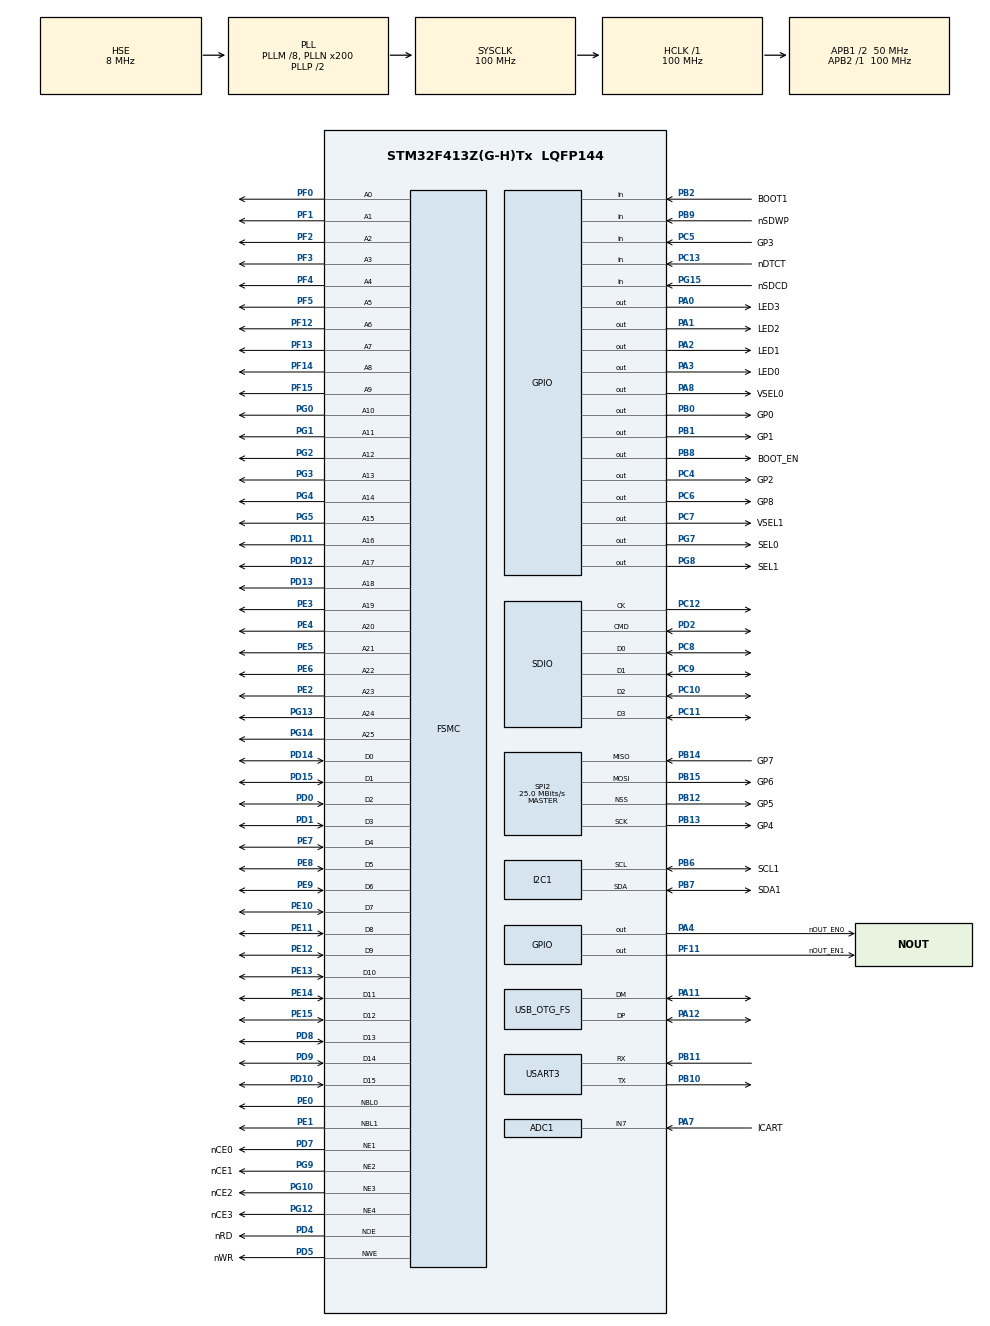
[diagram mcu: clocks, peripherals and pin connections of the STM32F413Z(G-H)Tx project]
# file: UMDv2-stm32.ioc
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SH.FSMC_D1_DA1.2=FSMC_D1,16b-d4
SH.FSMC_D1_DA1.1=FSMC_D1,8b-d2
SH.FSMC_D1_DA1.3=FSMC_D1,8b-d3
PD7.Mode=NorPsramChipSelect1_1
SH.FSMC_D1_DA1.0=FSMC_D1,8b-d1
FATFS0.BSP.api=Unknown
PG8.Signal=GPIO_Output
SH.FSMC_NWE.0=FSMC_NWE,Sram2
PG0.Signal=FSMC_A10
SH.FSMC_NWE.3=FSMC_NWE,Sram3
SH.FSMC_NWE.1=FSMC_NWE,Sram4
SH.FSMC_NWE.2=FSMC_NWE,Sram1
Dma.MEMTOMEM.1.FIFOMode=DMA_FIFOMODE_ENABLE
PG15.GPIO_Label=nSDCD
PB0.Stacked=true
RCC.APB2TimFreq_Value=100000000
PB6.Signal=I2C1_SCL
PC7.Signal=GPIO_Output
PD0.Signal=FSMC_D2_DA2
PD8.Signal=FSMC_D13_DA13
PE1.Signal=FSMC_NBL1
FATFS0.BSP.ip=GPIO
PB3.Mode=JTAG_5_pins
PB12.GPIO_Label=GP5
SH.FSMC_D10_DA10.0=FSMC_D10,16b-d4
PC4.GPIO_Label=GP2
PE9.Signal=FSMC_D6_DA6
PB1.GPIO_Label=GP1
PC9.Mode=SD_4_bits_Wide_bus
PA8.Signal=GPIO_Output
SH.FSMC_D5_DA5.0=FSMC_D5,8b-d1
SH.FSMC_D5_DA5.3=FSMC_D5,8b-d3
SH.FSMC_D5_DA5.1=FSMC_D5,8b-d2
PA0.Signal=GPIO_Output
SH.FSMC_D5_DA5.2=FSMC_D5,16b-d4
Mcu.Package=LQFP144
PB9.Signal=GPIO_Input
PB1.Signal=SharedStack_PB1
Dma.MEMTOMEM.1.Instance=DMA2_Stream1
SPI2.Mode=SPI_MODE_MASTER
PD12.Signal=FSMC_A17
PC11.Mode=SD_4_bits_Wide_bus
SH.FSMC_A1.1=FSMC_A1,26b-a3
SH.FSMC_A1.2=FSMC_A1,26b-a2
SH.FSMC_A1.0=FSMC_A1,26b-a1
SH.FSMC_A1.3=FSMC_A1,26b-a4
RCC.APB1TimFreq_Value=100000000
FSMC.WriteOperation3=FSMC_WRITE_OPERATION_ENABLE
FSMC.WriteOperation4=FSMC_WRITE_OPERATION_ENABLE
PA4.GPIO_Label=nOUT_EN0
PD15.Signal=FSMC_D1_DA1
PG12.Signal=FSMC_NE4
FSMC.ExtendedAddressSetupTime1=2
FATFS0.BSP.STBoard=false
FSMC.ExtendedAddressSetupTime2=2
FSMC.ExtendedAddressSetupTime3=2
FSMC.ExtendedAddressSetupTime4=2
SH.FSMC_A16.1=FSMC_A16,26b-a3
SH.FSMC_A16.2=FSMC_A16,26b-a2
Dma.MEMTOMEM.0.Priority=DMA_PRIORITY_LOW
SH.FSMC_A16.0=FSMC_A16,26b-a1
SH.FSMC_A16.3=FSMC_A16,26b-a4
PG5.Signal=FSMC_A15
PC13.Signal=GPIO_Input
FATFS0.BSP.mode=Input
PH1\ -\ OSC_OUT.Mode=HSE-External-Oscillator
PG9.Mode=NorPsramChipSelect2_2
SH.FSMC_D9_DA9.0=FSMC_D9,16b-d4
SH.FSMC_D8_DA8.0=FSMC_D8,16b-d4
PD10.Signal=FSMC_D15_DA15
PB8.GPIO_Label=BOOT_EN
PA8.GPIO_Label=VSEL0
SH.FSMC_A3.0=FSMC_A3,26b-a1
SH.FSMC_A3.3=FSMC_A3,26b-a4
SH.FSMC_A3.1=FSMC_A3,26b-a3
SH.FSMC_A3.2=FSMC_A3,26b-a2
Dma.MEMTOMEM.0.MemBurst=DMA_MBURST_SINGLE
PB14.Signal=SharedStack_PB14
PC12.Mode=SD_4_bits_Wide_bus
Dma.MEMTOMEM.1.MemDataAlignment=DMA_MDATAALIGN_HALFWORD
PE14.Signal=FSMC_D11_DA11
Dma.MEMTOMEM.1.PeriphDataAlignment=DMA_PDATAALIGN_HALFWORD
PB15.GPIO_Label=GP6
PC4.Stacked=true
SH.FSMC_A18.0=FSMC_A18,26b-a1
PG7.GPIO_Label=SEL0
SH.FSMC_A18.3=FSMC_A18,26b-a4
PA1.GPIO_Label=LED2
SH.FSMC_A18.1=FSMC_A18,26b-a3
SH.FSMC_A18.2=FSMC_A18,26b-a2
PF13.Signal=FSMC_A7
PC7.GPIO_Label=VSEL1
PC8.Mode=SD_4_bits_Wide_bus
ADC1.master=1
ProjectManager.HeapSize=0x200
SH.FSMC_A5.1=FSMC_A5,26b-a3
SH.FSMC_A5.2=FSMC_A5,26b-a2
NVIC.PriorityGroup=NVIC_PRIORITYGROUP_4
SH.FSMC_A5.0=FSMC_A5,26b-a1
SH.FSMC_A5.3=FSMC_A5,26b-a4
PE3.Signal=FSMC_A19
Dma.MEMTOMEM.0.Direction=DMA_MEMORY_TO_MEMORY
PF4.Signal=FSMC_A4
PB15.Stacked=true
PD2.Signal=SDIO_CMD
FATFS0.BSP.name=Detect_SDIO
Mcu.Family=STM32F4
USB_DEVICE.CLASS_NAME_FS=CDC
SPI2.VirtualNSS=VM_NSSHARD
SH.SharedStack_PB14.0=SPI2_MISO,Full_Duplex_Master
SH.SharedStack_PB14.1=GPIO_Input+0
SH.SharedStack_PB14.2=GPIO_Output+0
SH.FSMC_A6.0=FSMC_A6,26b-a1
SH.FSMC_A6.1=FSMC_A6,26b-a3
PG2.Signal=FSMC_A12
SH.FSMC_A6.2=FSMC_A6,26b-a2
SH.FSMC_A6.3=FSMC_A6,26b-a4
SH.FSMC_D0_DA0.1=FSMC_D0,8b-d2
SH.FSMC_D0_DA0.2=FSMC_D0,16b-d4
PA0.GPIO_Label=LED3
SH.FSMC_D0_DA0.0=FSMC_D0,8b-d1
SH.FSMC_D0_DA0.3=FSMC_D0,8b-d3
PA11.Mode=Device_Only
PB13.GPIO_Label=GP4
PB15.Signal=SharedStack_PB15
PG15.Signal=GPIO_Input
PD13.Signal=FSMC_A18
SH.FSMC_A11.2=FSMC_A11,26b-a2
SH.FSMC_A11.3=FSMC_A11,26b-a4
SH.FSMC_A11.0=FSMC_A11,26b-a1
SH.FSMC_A11.1=FSMC_A11,26b-a3
PH0\ -\ OSC_IN.Signal=RCC_OSC_IN
SH.SharedStack_PC5.1=GPIO_Output
SH.FSMC_A22.2=FSMC_A22,26b-a2
SH.FSMC_A22.3=FSMC_A22,26b-a4
SH.FSMC_A22.0=FSMC_A22,26b-a1
SH.FSMC_A22.1=FSMC_A22,26b-a3
SH.SharedStack_PC5.0=GPIO_Input+0
ADC1.Channel-0\#ChannelRegularConversion=ADC_CHANNEL_7
FSMC.WriteFifo1=FSMC_WRITE_FIFO_ENABLE
RCC.HSE_VALUE=8000000
SH.FSMC_NBL0.0=FSMC_NBL0,2ByteEnable4
Dma.MEMTOMEM.1.MemBurst=DMA_MBURST_SINGLE
SH.SharedStack_PB12.0=SPI2_NSS,NSS_Signal_Hard_Output
PB1.Stacked=true
SH.SharedStack_PB12.1=GPIO_Input+0
SH.SharedStack_PB12.2=GPIO_Output+0
SH.FSMC_D14_DA14.0=FSMC_D14,16b-d4
PA14.Mode=JTAG_5_pins
PF11.Signal=GPIO_Output
SH.FSMC_D6_DA6.0=FSMC_D6,8b-d1
SH.FSMC_D6_DA6.1=FSMC_D6,8b-d2
SH.FSMC_D6_DA6.2=FSMC_D6,16b-d4
SH.FSMC_A8.2=FSMC_A8,26b-a2
SH.FSMC_D6_DA6.3=FSMC_D6,8b-d3
SH.FSMC_A8.3=FSMC_A8,26b-a4
SH.FSMC_A8.0=FSMC_A8,26b-a1
SH.FSMC_A8.1=FSMC_A8,26b-a3
PB7.Signal=I2C1_SDA
SH.FSMC_D4_DA4.3=FSMC_D4,8b-d3
SH.FSMC_D4_DA4.2=FSMC_D4,16b-d4
SH.FSMC_D4_DA4.1=FSMC_D4,8b-d2
SH.FSMC_D4_DA4.0=FSMC_D4,8b-d1
PB7.GPIO_Label=SDA1
Dma.MEMTOMEM.1.PeriphBurst=DMA_PBURST_SINGLE
PD5.GPIO_Label=nWR
NVIC.OTG_FS_IRQn=true\:0\:0\:false\:false\:true\:false\:true
SH.FSMC_D13_DA13.0=FSMC_D13,16b-d4
PA15.Signal=SYS_JTDI
SH.FSMC_A13.0=FSMC_A13,26b-a1
SH.FSMC_A13.1=FSMC_A13,26b-a3
PC5.Stacked=true
SH.FSMC_A13.2=FSMC_A13,26b-a2
SH.FSMC_A13.3=FSMC_A13,26b-a4
Dma.Request1=MEMTOMEM
SH.FSMC_D2_DA2.3=FSMC_D2,8b-d3
SH.FSMC_D2_DA2.2=FSMC_D2,16b-d4
SH.FSMC_D2_DA2.1=FSMC_D2,8b-d2
SH.FSMC_D2_DA2.0=FSMC_D2,8b-d1
PC5.Signal=SharedStack_PC5
PE7.Signal=FSMC_D4_DA4
Dma.Request0=MEMTOMEM
SH.FSMC_A24.0=FSMC_A24,26b-a1
SH.FSMC_A24.1=FSMC_A24,26b-a3
SH.FSMC_A24.2=FSMC_A24,26b-a2
SH.FSMC_A24.3=FSMC_A24,26b-a4
PB4.Signal=SYS_JTRST
PA3.Signal=GPIO_Output
Dma.MEMTOMEM.0.MemDataAlignment=DMA_MDATAALIGN_BYTE
SH.FSMC_D12_DA12.0=FSMC_D12,16b-d4
PG7.Signal=GPIO_Output
SH.SharedStack_PB0.0=GPIO_Output+0
SH.SharedStack_PB0.1=GPIO_Input
FSMC.ExtendedMode3=FSMC_EXTENDED_MODE_ENABLE
FSMC.ExtendedMode4=FSMC_EXTENDED_MODE_ENABLE
FSMC.ExtendedMode1=FSMC_EXTENDED_MODE_ENABLE
FSMC.ExtendedMode2=FSMC_EXTENDED_MODE_ENABLE
PC11.Signal=SDIO_D3
PC8.Signal=SDIO_D0
PC10.Mode=SD_4_bits_Wide_bus
PD9.Signal=FSMC_D14_DA14
FATFS0.BSP.instance=PG15
PG8.GPIO_Label=SEL1
PA13.Signal=SYS_JTMS-SWDIO
PH0\ -\ OSC_IN.Mode=HSE-External-Oscillator
RCC.USBFreq_Value=48000000
Dma.MEMTOMEM.0.FIFOMode=DMA_FIFOMODE_ENABLE
PA1.Signal=GPIO_Output
PD2.Mode=SD_4_bits_Wide_bus
board=custom
PG12.Mode=NorPsramChipSelect4_4
RCC.VCOOutputFreq_Value=200000000
PF1.Signal=FSMC_A1
PE0.Signal=FSMC_NBL0
FSMC.AccessMode1=FSMC_ACCESS_MODE_A
PE12.Signal=FSMC_D9_DA9
Dma.MEMTOMEM.0.PeriphDataAlignment=DMA_PDATAALIGN_BYTE
RCC.SYSCLKFreq_VALUE=100000000
Dma.MEMTOMEM.0.Mode=DMA_NORMAL
Dma.MEMTOMEM.0.MemInc=DMA_MINC_ENABLE
USART3.VirtualMode=VM_ASYNC
SH.FSMC_A20.0=FSMC_A20,26b-a1
SH.FSMC_A20.1=FSMC_A20,26b-a3
PB2.GPIO_Label=BOOT1
SH.FSMC_NOE.3=FSMC_NOE,Sram3
SH.FSMC_D11_DA11.0=FSMC_D11,16b-d4
SH.FSMC_NOE.2=FSMC_NOE,Sram1
SH.FSMC_NOE.1=FSMC_NOE,Sram4
SH.FSMC_NOE.0=FSMC_NOE,Sram2
PB12.Stacked=true
RCC.PLLM=8
RCC.PLLN=200
VP_CRC_VS_CRC.Mode=CRC_Activate
SH.FSMC_A20.2=FSMC_A20,26b-a2
SH.FSMC_A20.3=FSMC_A20,26b-a4
RCC.PLLI2SQ=4
PB12.Signal=SharedStack_PB12
FSMC.ExtendedAddressHoldTime1=4
PA3.GPIO_Label=LED0
RCC.PLLI2SM=8
FSMC.ExtendedAccessMode1=FSMC_ACCESS_MODE_A
SPI2.VirtualType=VM_MASTER
PB10.Mode=Asynchronous
VP_FATFS_VS_SDIO.Mode=SDIO
PG4.Signal=FSMC_A14
PC12.Signal=SDIO_CK
PB14.GPIO_Label=GP7
FSMC.ExtendedBusTurnAroundDuration3=2
FSMC.ExtendedBusTurnAroundDuration2=2
FSMC.ExtendedBusTurnAroundDuration4=12
PC6.GPIO_Label=GP8
PB6.GPIO_Label=SCL1
FSMC.ExtendedBusTurnAroundDuration1=2
PB13.Signal=SharedStack_PB13
PG13.Signal=FSMC_A24
Dma.MEMTOMEM.1.Priority=DMA_PRIORITY_LOW
RCC.SYSCLKSource=RCC_SYSCLKSOURCE_PLLCLK
SH.FSMC_A19.2=FSMC_A19,26b-a2
SH.FSMC_A19.3=FSMC_A19,26b-a4
SH.FSMC_A19.0=FSMC_A19,26b-a1
SH.FSMC_A19.1=FSMC_A19,26b-a3
PD4.Signal=FSMC_NOE
PB6.Mode=I2C
PE5.Signal=FSMC_A21
PB2.Signal=GPIO_Input
FATFS0.BSP.i2caddr=0
SH.FSMC_A0.2=FSMC_A0,26b-a2
SH.FSMC_A0.3=FSMC_A0,26b-a4
SH.FSMC_A0.0=FSMC_A0,26b-a1
SH.FSMC_A0.1=FSMC_A0,26b-a3
Dma.MEMTOMEM.0.Instance=DMA2_Stream0
SPI2.CalculateBaudRate=25.0 MBits/s
PE2.Signal=FSMC_A23
FSMC.BusTurnAroundDuration1=2
FSMC.BusTurnAroundDuration2=2
PF3.Signal=FSMC_A3
PE10.Signal=FSMC_D7_DA7
PB14.Stacked=true
ADC1.SamplingTime-0\#ChannelRegularConversion=ADC_SAMPLETIME_3CYCLES
Dma.MEMTOMEM.0.PeriphInc=DMA_PINC_ENABLE
FATFS0.BSP.solution=PG15
Dma.MEMTOMEM.1.FIFOThreshold=DMA_FIFO_THRESHOLD_FULL
SH.FSMC_D3_DA3.2=FSMC_D3,16b-d4
SH.FSMC_D3_DA3.1=FSMC_D3,8b-d2
SH.FSMC_D3_DA3.3=FSMC_D3,8b-d3
FSMC.BusTurnAroundDuration3=2
FSMC.BusTurnAroundDuration4=2
SH.FSMC_D3_DA3.0=FSMC_D3,8b-d1
PF14.Signal=FSMC_A8
ADC1.Rank-0\#ChannelRegularConversion=1
SH.FSMC_A2.0=FSMC_A2,26b-a1
SH.FSMC_A2.1=FSMC_A2,26b-a3
SH.FSMC_A2.2=FSMC_A2,26b-a2
SH.FSMC_A2.3=FSMC_A2,26b-a4
PG9.Signal=FSMC_NE2
PC6.Signal=SharedStack_PC6
PD7.Signal=FSMC_NE1
PD1.Signal=FSMC_D3_DA3
RCC.APB1CLKDivider=RCC_HCLK_DIV2
PG10.Signal=FSMC_NE3
PB11.Mode=Asynchronous
SH.FSMC_A15.2=FSMC_A15,26b-a2
FSMC.DataSetupTime4=12
SH.FSMC_A15.3=FSMC_A15,26b-a4
FSMC.DataSetupTime3=12
SH.FSMC_A15.0=FSMC_A15,26b-a1
FSMC.DataSetupTime2=12
USB_DEVICE.PRODUCT_STRING_CDC_FS=UMDv2
SH.FSMC_A15.1=FSMC_A15,26b-a3
FSMC.DataSetupTime1=12
SH.ADCx_IN7.0=ADC1_IN7,IN7
PB10.Signal=USART3_TX
FATFS.BSP.number=1
RCC.USBCLockSelection=RCC_CLK48CLKSOURCE_PLLI2SQ
SH.FSMC_D7_DA7.3=FSMC_D7,8b-d3
Dma.MEMTOMEM.1.Mode=DMA_NORMAL
SH.FSMC_D7_DA7.1=FSMC_D7,8b-d2
SH.FSMC_D7_DA7.2=FSMC_D7,16b-d4
SH.FSMC_D7_DA7.0=FSMC_D7,8b-d1
PH1\ -\ OSC_OUT.Signal=RCC_OSC_OUT
PE15.Signal=FSMC_D12_DA12
PE8.Signal=FSMC_D5_DA5
SH.FSMC_A4.2=FSMC_A4,26b-a2
SH.FSMC_A4.3=FSMC_A4,26b-a4
SH.FSMC_A4.0=FSMC_A4,26b-a1
SH.FSMC_A4.1=FSMC_A4,26b-a3
Dma.MEMTOMEM.1.Direction=DMA_MEMORY_TO_MEMORY
PA13.Mode=JTAG_5_pins
PA4.Signal=GPIO_Output
PD11.Signal=FSMC_A16
PA11.Signal=USB_OTG_FS_DM
SH.FSMC_D15_DA15.0=FSMC_D15,16b-d4
SH.FSMC_A17.0=FSMC_A17,26b-a1
SH.FSMC_A17.1=FSMC_A17,26b-a3
SH.FSMC_A17.2=FSMC_A17,26b-a2
SH.FSMC_A17.3=FSMC_A17,26b-a4
PB0.Signal=SharedStack_PB0
PG10.GPIO_Label=nCE2
FSMC.AddressSetupTime2=2
FSMC.AddressSetupTime1=2
FSMC.AddressSetupTime4=2
FSMC.AddressSetupTime3=2
RCC.CortexFreq_Value=100000000
PB13.Stacked=true
SH.FSMC_A12.1=FSMC_A12,26b-a3
SH.FSMC_A12.2=FSMC_A12,26b-a2
SH.FSMC_A12.0=FSMC_A12,26b-a1
SH.FSMC_A12.3=FSMC_A12,26b-a4
PC10.Signal=SDIO_D2
SH.SharedStack_PC6.0=GPIO_Output+0
SH.SharedStack_PC6.1=GPIO_Input
Dma.MEMTOMEM.1.PeriphInc=DMA_PINC_ENABLE
PB0.GPIO_Label=GP0
SH.FSMC_A23.1=FSMC_A23,26b-a3
SH.FSMC_A23.2=FSMC_A23,26b-a2
SH.FSMC_A23.0=FSMC_A23,26b-a1
PC13.GPIO_Label=nDTCT
SH.FSMC_A23.3=FSMC_A23,26b-a4
PB11.Signal=USART3_RX
ProjectManager.StackSize=0x400
USB_DEVICE.MANUFACTURER_STRING=db Electronics
SH.SharedStack_PB13.0=GPIO_Input+0
SH.SharedStack_PB13.1=GPIO_Output+0
SH.SharedStack_PB13.2=SPI2_SCK,Full_Duplex_Master
PA12.Signal=USB_OTG_FS_DP
SH.FSMC_A7.0=FSMC_A7,26b-a1
SH.FSMC_A7.3=FSMC_A7,26b-a4
RCC.HCLKFreq_Value=100000000
SH.FSMC_A7.1=FSMC_A7,26b-a3
SH.FSMC_A7.2=FSMC_A7,26b-a2
PF11.GPIO_Label=nOUT_EN1
PF12.Signal=FSMC_A6
SH.FSMC_A10.0=FSMC_A10,26b-a1
RCC.AHBFreq_Value=100000000
PA15.Mode=JTAG_5_pins
PB4.Mode=JTAG_5_pins
PE13.Signal=FSMC_D10_DA10
SH.FSMC_A14.0=FSMC_A14,26b-a1
SH.FSMC_A14.3=FSMC_A14,26b-a4
SH.FSMC_A14.1=FSMC_A14,26b-a3
SH.FSMC_A14.2=FSMC_A14,26b-a2
PE4.Signal=FSMC_A20
SH.FSMC_A25.0=FSMC_A25,26b-a1
SH.SharedStack_PC4.0=GPIO_Output+0
PD7.GPIO_Label=nCE0
SH.FSMC_A25.3=FSMC_A25,26b-a4
SH.SharedStack_PC4.1=GPIO_Input
SH.FSMC_A25.1=FSMC_A25,26b-a3
SH.FSMC_A25.2=FSMC_A25,26b-a2
Dma.MEMTOMEM.1.MemInc=DMA_MINC_ENABLE
SH.FSMC_NBL1.0=FSMC_NBL1,2ByteEnable4
PA2.GPIO_Label=LED1
USB_OTG_FS.VirtualMode=Device_Only
Dma.MEMTOMEM.0.FIFOThreshold=DMA_FIFO_THRESHOLD_FULL
SH.SharedStack_PB1.1=GPIO_Input
SH.SharedStack_PB1.0=GPIO_Output+0
PF5.Signal=FSMC_A5
SH.FSMC_A9.1=FSMC_A9,26b-a3
SH.FSMC_A9.2=FSMC_A9,26b-a2
SH.FSMC_A9.0=FSMC_A9,26b-a1
SH.FSMC_A9.3=FSMC_A9,26b-a4
SPI2.Direction=SPI_DIRECTION_2LINES
PF0.Signal=FSMC_A0
PC6.Stacked=true
PB9.GPIO_Label=nSDWP
FSMC.WriteOperation1=FSMC_WRITE_OPERATION_ENABLE
FSMC.WriteOperation2=FSMC_WRITE_OPERATION_ENABLE
USB_DEVICE.VirtualModeFS=Cdc_FS
PG3.Signal=FSMC_A13
PG1.Signal=FSMC_A11
PC4.Signal=SharedStack_PC4
PG10.Mode=NorPsramChipSelect3_3
PD5.Signal=FSMC_NWE
FSMC.AddressHoldTime1=4
ProjectManager.TargetToolchain=STM32CubeIDE
VP_USB_DEVICE_VS_USB_DEVICE_CDC_FS.Mode=CDC_FS
PF2.Signal=FSMC_A2
PE11.Signal=FSMC_D8_DA8
FSMC.ExtendedDataSetupTime4=12
PG9.GPIO_Label=nCE1
PG14.Signal=FSMC_A25
FSMC.ExtendedDataSetupTime1=12
FSMC.ExtendedDataSetupTime2=12
FSMC.ExtendedDataSetupTime3=12
RCC.APB2Freq_Value=100000000
SH.FSMC_A21.0=FSMC_A21,26b-a1
SH.FSMC_A10.3=FSMC_A10,26b-a4
SH.FSMC_A10.1=FSMC_A10,26b-a3
SH.FSMC_A10.2=FSMC_A10,26b-a2
PD4.GPIO_Label=nRD
PF15.Signal=FSMC_A9
PE6.Signal=FSMC_A22
Mcu.Name=STM32F413Z(G-H)Tx
SH.FSMC_A21.3=FSMC_A21,26b-a4
PA2.Signal=GPIO_Output
SH.FSMC_A21.1=FSMC_A21,26b-a3
SH.FSMC_A21.2=FSMC_A21,26b-a2
PD14.Signal=FSMC_D0_DA0
PB3.Signal=SYS_JTDO-SWO
PA7.GPIO_Label=ICART
PA12.Mode=Device_Only
Dma.MEMTOMEM.0.PeriphBurst=DMA_PBURST_SINGLE
PC5.GPIO_Label=GP3
PB7.Mode=I2C
SH.SharedStack_PB15.0=SPI2_MOSI,Full_Duplex_Master
SH.SharedStack_PB15.1=GPIO_Input+0
PA14.Signal=SYS_JTCK-SWCLK
SH.SharedStack_PB15.2=GPIO_Output+0
PG12.GPIO_Label=nCE3
ADC1.NbrOfConversionFlag=1
PB8.Signal=GPIO_Output
PC9.Signal=SDIO_D1
RCC.APB1Freq_Value=50000000
USB_DEVICE.VirtualMode=Cdc
PA7.Signal=ADCx_IN7

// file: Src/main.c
/* USER CODE BEGIN Header */
/**
  ******************************************************************************
  * @file           : main.c
  * @brief          : Main program body
  ******************************************************************************
  * @attention
  *
  * <h2><center>&copy; Copyright (c) 2019 STMicroelectronics.
  * All rights reserved.</center></h2>
  *
  * This software component is licensed by ST under BSD 3-Clause license,
  * the "License"; You may not use this file except in compliance with the
  * License. You may obtain a copy of the License at:
  *                        opensource.org/licenses/BSD-3-Clause
  *
  ******************************************************************************
  */
/* USER CODE END Header */
#include "main.h"
#include "adc.h"
#include "crc.h"
#include "dma.h"
#include "fatfs.h"
#include "i2c.h"
#include "sdio.h"
#include "spi.h"
#include "usart.h"
#include "usb_device.h"
#include "gpio.h"
#include "fsmc.h"

/* USER CODE BEGIN Includes */
#include "UMD-App/UMD.h"
/* USER CODE END Includes */

void SystemClock_Config(void);

int main(void)
{

  /* MCU Configuration--------------------------------------------------------*/

  /* Reset of all peripherals, Initializes the Flash interface and the Systick. */
  HAL_Init();

  /* Configure the system clock */
  SystemClock_Config();

  /* Initialize all configured peripherals */
  MX_GPIO_Init();
  MX_DMA_Init();
  MX_ADC1_Init();
  MX_CRC_Init();
  MX_FSMC_Init();
  MX_I2C1_Init();
  MX_SDIO_SD_Init();
  MX_SPI2_Init();
  MX_USART3_UART_Init();
  MX_FATFS_Init();
  MX_USB_DEVICE_Init();

  /* Infinite loop */
  while (1)
  {

    /* USER CODE BEGIN 3 */
	  UMD UMDapp;
	  UMDapp.run();

  }
  /* USER CODE END 3 */
}

void SystemClock_Config(void)
{
  RCC_OscInitTypeDef RCC_OscInitStruct = {0};
  RCC_ClkInitTypeDef RCC_ClkInitStruct = {0};
  RCC_PeriphCLKInitTypeDef PeriphClkInitStruct = {0};

  /** Configure the main internal regulator output voltage
  */
  __HAL_RCC_PWR_CLK_ENABLE();
  __HAL_PWR_VOLTAGESCALING_CONFIG(PWR_REGULATOR_VOLTAGE_SCALE1);
  /** Initializes the RCC Oscillators according to the specified parameters
  * in the RCC_OscInitTypeDef structure.
  */
  RCC_OscInitStruct.OscillatorType = RCC_OSCILLATORTYPE_HSE;
  RCC_OscInitStruct.HSEState = RCC_HSE_ON;
  RCC_OscInitStruct.PLL.PLLState = RCC_PLL_ON;
  RCC_OscInitStruct.PLL.PLLSource = RCC_PLLSOURCE_HSE;
  RCC_OscInitStruct.PLL.PLLM = 8;
  RCC_OscInitStruct.PLL.PLLN = 200;
  RCC_OscInitStruct.PLL.PLLP = RCC_PLLP_DIV2;
  RCC_OscInitStruct.PLL.PLLQ = 2;
  RCC_OscInitStruct.PLL.PLLR = 2;
  if (HAL_RCC_OscConfig(&RCC_OscInitStruct) != HAL_OK)
  {
    Error_Handler();
  }
  /** Initializes the CPU, AHB and APB buses clocks
  */
  RCC_ClkInitStruct.ClockType = RCC_CLOCKTYPE_HCLK|RCC_CLOCKTYPE_SYSCLK
                              |RCC_CLOCKTYPE_PCLK1|RCC_CLOCKTYPE_PCLK2;
  RCC_ClkInitStruct.SYSCLKSource = RCC_SYSCLKSOURCE_PLLCLK;
  RCC_ClkInitStruct.AHBCLKDivider = RCC_SYSCLK_DIV1;
  RCC_ClkInitStruct.APB1CLKDivider = RCC_HCLK_DIV2;
  RCC_ClkInitStruct.APB2CLKDivider = RCC_HCLK_DIV1;

  if (HAL_RCC_ClockConfig(&RCC_ClkInitStruct, FLASH_LATENCY_3) != HAL_OK)
  {
    Error_Handler();
  }
  PeriphClkInitStruct.PeriphClockSelection = RCC_PERIPHCLK_SDIO|RCC_PERIPHCLK_CLK48;
  PeriphClkInitStruct.PLLI2S.PLLI2SN = 192;
  PeriphClkInitStruct.PLLI2S.PLLI2SM = 8;
  PeriphClkInitStruct.PLLI2S.PLLI2SR = 2;
  PeriphClkInitStruct.PLLI2S.PLLI2SQ = 4;
  PeriphClkInitStruct.Clk48ClockSelection = RCC_CLK48CLKSOURCE_PLLI2SQ;
  PeriphClkInitStruct.SdioClockSelection = RCC_SDIOCLKSOURCE_CLK48;
  PeriphClkInitStruct.PLLI2SSelection = RCC_PLLI2SCLKSOURCE_PLLSRC;
  if (HAL_RCCEx_PeriphCLKConfig(&PeriphClkInitStruct) != HAL_OK)
  {
    Error_Handler();
  }
}

void Error_Handler(void)
{
}

/************************ (C) COPYRIGHT STMicroelectronics *****END OF FILE****/
